# Polarfire SoC register map
Vendor: Microchip; File version: 1.0
CPU: Microchip PolarFire SoC 1.0, little endian
Registers are 32-bit, read-write, reset 0x0 unless marked. A register's access mark holds for its fields unless they carry their own. Offsets are from the block's base; [hi:lo] are bit positions; lines under a group give offsets from that group; {n}, {i} and the like mark numbered series; 'fields as' and 'values as' point back to an identical list.

## TRACE — TRACE Controller
Base 0x23000000
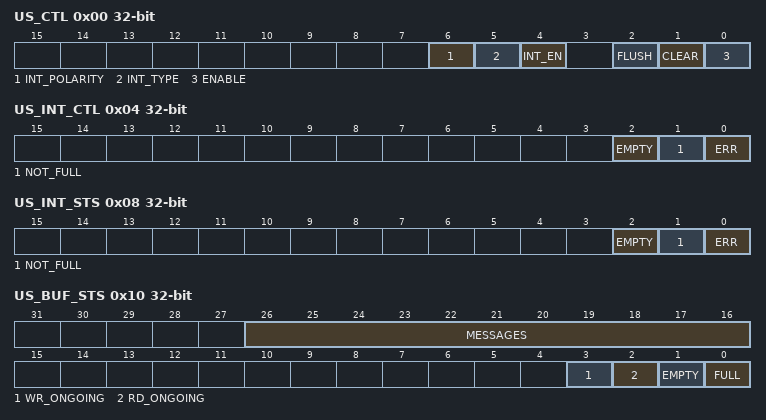
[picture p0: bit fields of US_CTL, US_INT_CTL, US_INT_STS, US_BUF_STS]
0x00 US_CTL — Upstream general control
  [6] INT_POLARITY — Upstream interrupt output is active high when this bit is 1. or active low when 0. Initial value at reset is set according to an instantiation parameter. so it should not be necessary to change the value of this bit.
  [5] INT_TYPE — Upstream interrupt output is a pulse when this bit is 1. or a level when it is 0
  [4] INT_EN — Upstream master interrupt enable
  [2] FLUSH — Flush the message currently being written from upstream message buffer. Must be applied before the last write of a message. Selfclearing. so always reads as zero
  [1] CLEAR — Clear upstream message buffer. Debug option; do not set without consulting UltraSoC
  [0] ENABLE — Upstream enable.
0x04 US_INT_CTL — control of upstream interrupt behaviour
  [2] EMPTY — Enable buffer empty interrupt
  [1] NOT_FULL — Enable buffer not full interrupt
  [0] ERR — Enable upstream error interrupt
0x08 US_INT_STS — upstream interrupt status
  [2] EMPTY — Enable buffer empty interrupt. The upstream message buffer is empty. and there is therefore sufficient space to write an entire message via us_data.
  [1] NOT_FULL — Enable buffer not full interrupt. The upstream message buffer is no longer full. and further message data can be written via us_data
  [0] ERR — Enable upstream error interrupt. This indicates us_data was written when there was no space available in the upstream message buffer (us_buf_sts full bit set).
0x0C US_DATA ro — Upstream message data
  [31:0] DATA rw
0x10 US_BUF_STS ro — upstream buffer status
  [26:16] MESSAGES — Number of whole messages contained in the upstream buffer.
  [3] WR_ONGOING — Write ongoing. Part of a message has been written in to the buffer via us_data.
  [2] RD_ONGOING — Read ongoing. Part of a message has been output from the message interface
  [1] EMPTY — Upstream buffer is empty
  [0] FULL — Upstream buffer is full
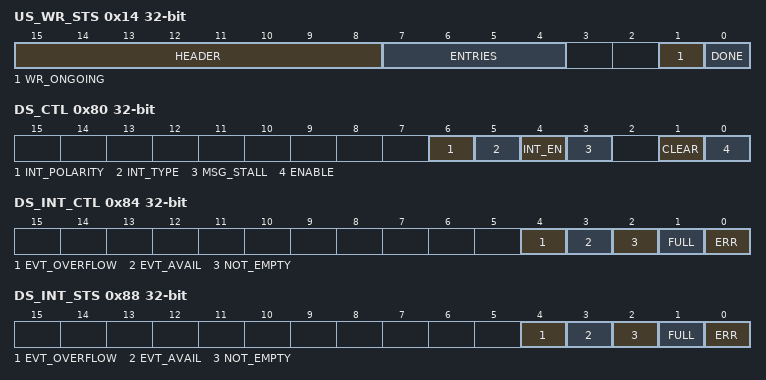
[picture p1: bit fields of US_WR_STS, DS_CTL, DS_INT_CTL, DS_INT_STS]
0x14 US_WR_STS ro — Upstream write status
  [15:8] HEADER — Header (byte 0) of the message being written into upstream message buffer (only valid if wr_ongoing is 1).
  [7:4] ENTRIES — Number of 32-bit words of an incomplete message written into the upstream buffer (only valid if wr_ongoing is 1).
  [1] WR_ONGOING — Write ongoing. Part of a message has been written in to the buffer via us_data
  [0] DONE — Upstream buffer contains a complete message
0x18 US_GP — Upstream general purpose
  [7:0] GP — General purpose location
0x1C US_EVT — Upstream event
  [7:0] EVENT — Event number to send
0x80 DS_CTL — Downstream general control
  [6] INT_POLARITY — Downstream interrupt output is active high when this bit is 1. or active low when 0. Initial value at reset is set according to an instantiation parameter. so it should not be necessary to change the value of this bit
  [5] INT_TYPE — Downstream interrupt output is a pulse when this bit is 1. or a level when it is 0.
  [4] INT_EN — Downstream master interrupt enable.
  [3] MSG_STALL — Stall the downstream message interface to prevent new downstream data accumulating in the downstream buffer. Debug option; do not set without consulting UltraSoC.
  [1] CLEAR — Clear downstream message buffer. Debug option; do not set without consulting UltraSoC
  [0] ENABLE — Downstream enable
0x84 DS_INT_CTL — control of downstream interrupt behaviour
  [4] EVT_OVERFLOW — Enable event FIFO overflow interrupt
  [3] EVT_AVAIL — Enable event available interrupt
  [2] NOT_EMPTY — Enable buffer not empty interrupt
  [1] FULL — Enable buffer full interrupt.
  [0] ERR — Enable downstream error interrupt
0x88 DS_INT_STS — downstream interrupt status
  [4] EVT_OVERFLOW — Event FIFO overflow interrupt. A downstream event was lost because there was no room to store it in the downstream event FIFO
  [3] EVT_AVAIL — Event available interrupt. The downstream event FIFO is no longer empty
  [2] NOT_EMPTY — Downstream buffer not empty interrupt. A new message is available and can be read from ds_data.
  [1] FULL — Downstream buffer full interrupt. The downstream message buffer is full. indicating that no further messages can be accepted and backpressure is being applied to the downstream message interface
  [0] ERR — Downstream error interrupt. This indicates ds_data was read when there was no message data available
0x8C DS_DATA ro — Downstream message data
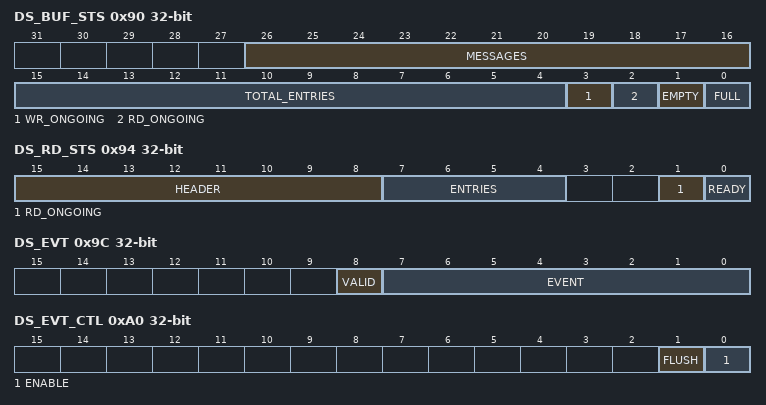
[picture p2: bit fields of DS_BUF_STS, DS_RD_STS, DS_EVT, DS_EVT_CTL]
0x90 DS_BUF_STS ro — Downstream buffer status
  [26:16] MESSAGES — Number of whole messages contained in the downstream buffer
  [15:4] TOTAL_ENTRIES — Number of buffer entries containing valid message data
  [3] WR_ONGOING — Write ongoing. Part of a message has been received from the message interface.
  [2] RD_ONGOING — Read ongoing. Part of a message has been read out of the buffer via ds_data
  [1] EMPTY — Downstream buffer is empty
  [0] FULL — Downstream buffer is full
0x94 DS_RD_STS ro — downstream read status
  [15:8] HEADER — Header (byte 0) of the message being read from the downstream message buffer (only valid if rd_ongoing is 1).
  [7:4] ENTRIES — Number of 32-bit words of a message yet to be read out of the downstream buffer (only valid if rd_ongoing is 1).
  [1] RD_ONGOING — Read ongoing. Part of a message has been read out of the buffer via ds_data
  [0] READY — Downstream buffer contains a complete message ready for reading.
0x9C DS_EVT — Downstream event
  [8] VALID — Event valid
  [7:0] EVENT — Event number received (when valid is 1).
0xA0 DS_EVT_CTL — control of downstream real-time events
  [1] FLUSH — Flush the downstream event FIFO. Once set. all events will be discarded until a zero is written to this bit
  [0] ENABLE — Event FIFO enable. Must be set in order to receive events via ds_evt
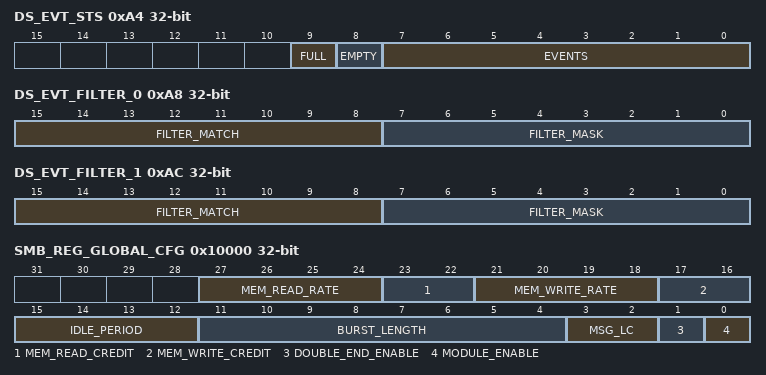
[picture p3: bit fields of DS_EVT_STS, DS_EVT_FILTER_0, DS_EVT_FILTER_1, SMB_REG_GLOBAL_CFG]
0xA4 DS_EVT_STS ro — status of downstream real-time events
  [9] FULL — Indicates that the downstream event FIFO is full
  [8] EMPTY — Indicates that the downstream event FIFO is empty
  [7:0] EVENTS — Number of events in the downstream event FIFO
0xA8 DS_EVT_FILTER_0 — Downstream event filter 0
  [15:8] FILTER_MATCH — Filter match. Capture all real-time events that meet the condition: event & filter_mask == filter_match & filter_mask
  [7:0] FILTER_MASK
0xAC DS_EVT_FILTER_1 — Downstream event filter 1
  fields as DS_EVT_FILTER_0
0x10000 SMB_REG_GLOBAL_CFG — Global configuration
  [27:24] MEM_READ_RATE — Controls the rate at which the read access credit counter is replenished in powers of 2.
  [23:22] MEM_READ_CREDIT — Controls the access credit available to the bus master for read accesses to the system memory.
  [21:18] MEM_WRITE_RATE — Controls the rate at which the write access credit counter is replenished in powers of 2. 0x0 replenishes continuously
  [17:16] MEM_WRITE_CREDIT — Controls the access credit available to the bus master for write accesses to the system memory.
  [15:12] IDLE_PERIOD — Controls the idle message injection timer period
  [11:4] BURST_LENGTH — Programmable burst length for system memory transfers. Defaults to the parameter sys_mem_blen_p
  [3:2] MSG_LC — The logical channel the network message adapter must output messages on.
  [1] DOUBLE_END_ENABLE — Read enable for double-ended buffering mode.
  [0] MODULE_ENABLE — Global enable for the System Memory Buffer. 0-Disable 1-Enable
0x10004 SMB_REG_GLOBAL_EN — Global enable
  [0] MODULE_ENABLE — Global enable for the System Memory Buffer. 0-Disable 1-Enable
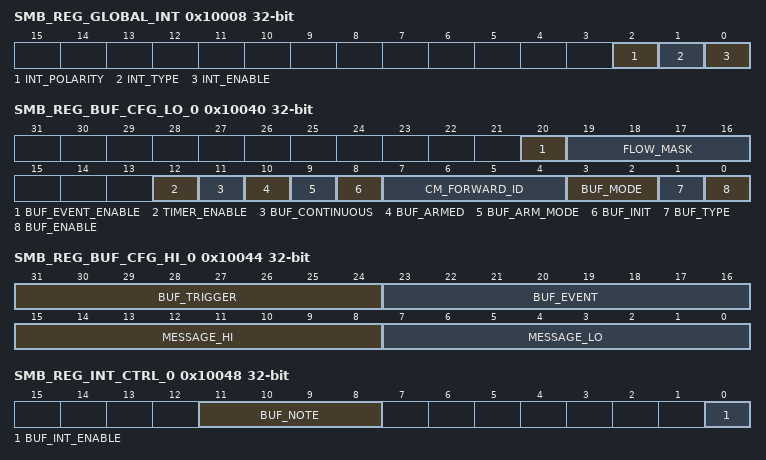
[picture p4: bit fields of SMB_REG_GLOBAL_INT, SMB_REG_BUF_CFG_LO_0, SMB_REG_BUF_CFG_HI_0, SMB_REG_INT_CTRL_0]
0x10008 SMB_REG_GLOBAL_INT — Global interrupt control
  [2] INT_POLARITY — Interrupt polarity: 1 - Active high. 0 - Active low.
  [1] INT_TYPE — Interrupt type: 1 - Pulse, 0 Level.
  [0] INT_ENABLE — Global interrupt enable control
0x1000C SMB_REG_GLOBAL_ID — Global master bus interface ID control
  [31:0] MST_ID
0x10040 SMB_REG_BUF_CFG_LO_0 — Logical buffer configuration (lower 32b) i logical buffer index; i = 0 for 1st buffer
  [20] BUF_EVENT_ENABLE — Enable event generation for the logical buffer when set
  [19:16] FLOW_MASK — Mask to filter the messages accepted based on their flow
  [12] TIMER_ENABLE — Controls whether the purge timer is enabled for a logical buffer. 0-Purge timer disabled 1-Purge timer enabled
  [11] BUF_CONTINUOUS — Set to make the buffer lossless by configuring it to block its message input when in a paused state.
  [10] BUF_ARMED — Set to arm the logical buffer in single shot mode
  [9] BUF_ARM_MODE — Set to enable single-shot mode. clear for automatic rearming
  [8] BUF_INIT — Initialises the buffer when set to 1, application of 0 has no effect. Read as zero
  [7:4] CM_FORWARD_ID — The communicator ID to forward the message stream to upon reading of the logical buffer
  [3:2] BUF_MODE — Buffering modes. 00 : Streaming mode (FIFO) 01 : Trace to mode 10 : Trace from mode 11 : Trace about mode
  [1] BUF_TYPE — Buffer control type: 0 : Double-ended buffering mode (default) 1 : Single-ended buffering mode
  [0] BUF_ENABLE — Logical buffer enable control: 0 : Disable the logical buffer 1 : Enable the logical buffer
0x10044 SMB_REG_BUF_CFG_HI_0 — Logical buffer configuration (upper 32b) i logical buffer index; i = 0 for 1st buffer
  [31:24] BUF_TRIGGER — The real-time event to accept as a trigger when the buffer is configured in a triggered mode
  [23:16] BUF_EVENT — The event to output when a buffer trigger occurs
  [15:8] MESSAGE_HI — Message filter range upper value
  [7:0] MESSAGE_LO — Message filter range lower value.
0x10048 SMB_REG_INT_CTRL_0 — Interrupt control
  [11:8] BUF_NOTE — Selects the buffer status changes that a debugger is to be notified about using a real-time event or interrupt.
  [0] BUF_INT_ENABLE — Logical buffer interrupts enable.
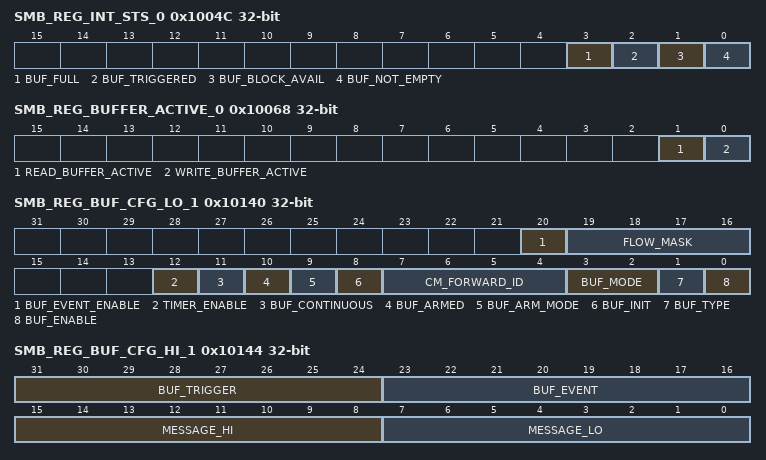
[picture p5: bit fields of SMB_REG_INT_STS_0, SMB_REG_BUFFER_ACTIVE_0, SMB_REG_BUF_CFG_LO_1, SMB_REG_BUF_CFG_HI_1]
0x1004C SMB_REG_INT_STS_0 — Interrupt status
  [3] BUF_FULL — Logical buffer full interrupt
  [2] BUF_TRIGGERED — Logical buffer triggered interrupt
  [1] BUF_BLOCK_AVAIL — Logical buffer memory block available to read interrupt.
  [0] BUF_NOT_EMPTY — Logical buffer changed to not empty interrupt.
0x10050 SMB_REG_BASE_LO_0 — Logical buffer base address (lower 32b)
  [31:0] BASE_ADDR_LO — Memory base address lower 32b for the message buffers
0x10054 SMB_REG_BASE_HI_0 — Logical buffer base address (upper 32b)
  [31:0] BASE_ADDR_HI — Memory base address upper 32b for the message buffers
0x10058 SMB_REG_LIMIT_0 — Logical buffer limit address
  [31:0] LIMIT_ADDR — Memory limit address configuring the end of a logical buffer
0x1005C SMB_REG_RD_ADDR_0 — Memory read address
  [31:0] READ_PTR — Memory read address pointer. Read only if the buffer is enabled in double ended mode
0x10060 SMB_REG_WR_ADDR_0 ro — Memory write address
  [31:0] WRITE_PTR — Memory write address pointer
0x10064 SMB_REG_PURGE_0 — Logical buffer purge
  [0] PURGE — Applying a 1 causes the packer and input FIFO of the logical buffer to be purged.
0x10068 SMB_REG_BUFFER_ACTIVE_0 ro — Logical buffer buffer active
  [1] READ_BUFFER_ACTIVE — Read operations from the buffer are active when 1
  [0] WRITE_BUFFER_ACTIVE — Write operations from the buffer are active when 1
0x10140 SMB_REG_BUF_CFG_LO_1 — Logical buffer configuration (lower 32b) i logical buffer index; i = 0 for 1st buffer
  fields as SMB_REG_BUF_CFG_LO_0
0x10144 SMB_REG_BUF_CFG_HI_1 — Logical buffer configuration (upper 32b) i logical buffer index; i = 0 for 1st buffer
  fields as SMB_REG_BUF_CFG_HI_0
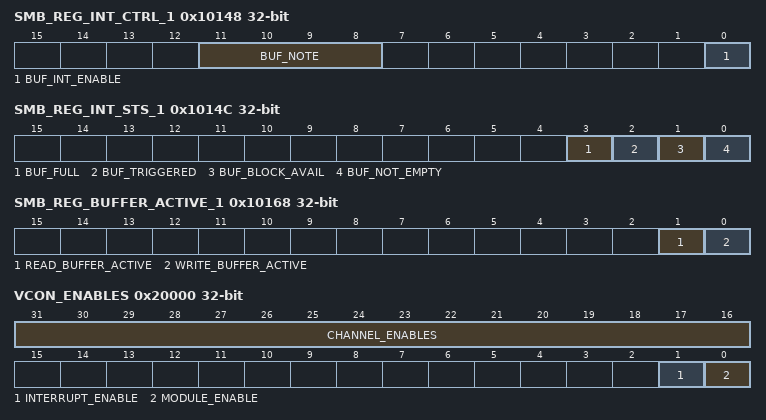
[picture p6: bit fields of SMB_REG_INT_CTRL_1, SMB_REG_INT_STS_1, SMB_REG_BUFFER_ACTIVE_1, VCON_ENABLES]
0x10148 SMB_REG_INT_CTRL_1 — Interrupt control
  fields as SMB_REG_INT_CTRL_0
0x1014C SMB_REG_INT_STS_1 — Interrupt status
  fields as SMB_REG_INT_STS_0
0x10150 SMB_REG_BASE_LO_1 — Logical buffer base address (lower 32b)
  fields as SMB_REG_BASE_LO_0
0x10154 SMB_REG_BASE_HI_1 — Logical buffer base address (upper 32b)
  fields as SMB_REG_BASE_HI_0
0x10158 SMB_REG_LIMIT_1 — Logical buffer limit address
  fields as SMB_REG_LIMIT_0
0x1015C SMB_REG_RD_ADDR_1 — Memory read address
  fields as SMB_REG_RD_ADDR_0
0x10160 SMB_REG_WR_ADDR_1 ro — Memory write address
  [31:0] WRITE_PTR — Memory write address pointer
0x10164 SMB_REG_PURGE_1 — Logical buffer purge
  fields as SMB_REG_PURGE_0
0x10168 SMB_REG_BUFFER_ACTIVE_1 ro — Logical buffer buffer active
  fields as SMB_REG_BUFFER_ACTIVE_0
0x20000 VCON_ENABLES — Virtual Console global enables register
  [31:16] CHANNEL_ENABLES — Channel enable. The enable for channel i corresponds to bit 16 + i.
  [1] INTERRUPT_ENABLE — Global interrupt enable
  [0] MODULE_ENABLE — Global module enable
0x20004 VCON_ENABLES_OR — Logical OR between the value written and the Virtual Console global enables register.
0x20008 VCON_ENABLES_AND — Logical AND between the value written and the Virtual Console group enables register
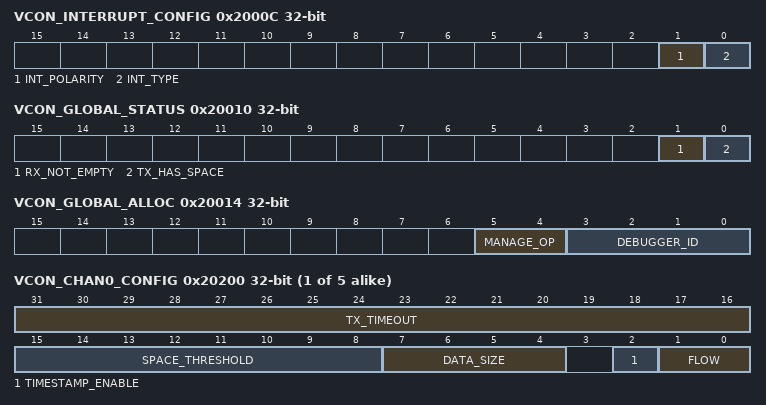
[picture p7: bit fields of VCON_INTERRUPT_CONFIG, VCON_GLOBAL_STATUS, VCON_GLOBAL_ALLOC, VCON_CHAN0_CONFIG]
0x2000C VCON_INTERRUPT_CONFIG — Virtual Console interrupt configuration register
  [1] INT_POLARITY — Interrupt polarity: 0: Active low. 1: Active high. Reset value defined at design time. It should not normally be necessary to change the value of this bit.
  [0] INT_TYPE — Interrupt type: 0: Level. 1: Pulse. Reset to 0.
0x20010 VCON_GLOBAL_STATUS ro — Virtual Console global status register
  [1] RX_NOT_EMPTY — Channel i upstream buffer not empty flag
  [0] TX_HAS_SPACE — Channel i downstream buffer has space flag
0x20014 VCON_GLOBAL_ALLOC — Virtual Console global allocation register
  [5:4] MANAGE_OP — Allocation operation: 00 (get): Requests allocation status of global resource 01 (allocate): Allocate global resource to debugger_id if currently unallocated. 10 (release): Deallocate global resource. 11 (force): Allocate global resource to debugger_id even if this resource is already allocated.
  [3:0] DEBUGGER_ID — ID of debugger or other software API. Zero means unallocated.
0x2007C VCON_CHAN0_BURSTDATA — Virtual Console channel 0 burst data register
  [31:0] BURSTDATA — Write transactions transfer data to the channel i upstream buffer. Read transactions retrieve data from the channel I downstream buffer.
{0x2001C+0xE0*i} VCON_CHAN{i}_BURSTDATA (i=1..4) — Virtual Console channel {i} burst data register
  fields as VCON_CHAN0_BURSTDATA
{0x20200+0x20*i} VCON_CHAN{i}_CONFIG (i=0..4) — Virtual Console channel {i} configuration register
  [31:16] TX_TIMEOUT — Transmit timeout in cycles
  [15:8] SPACE_THRESHOLD — Available space threshold for signalling an interrupt. An interrupt is issued when the available space is greater than this value
  [7:4] DATA_SIZE — The maximum length - in bytes - of the data field in vconsole_data messages. plus one.
  [2] TIMESTAMP_ENABLE — Enable timestamps on vconsole_data messages
  [1:0] FLOW — The flow assigned to flow_control_report and vconsole_data messages
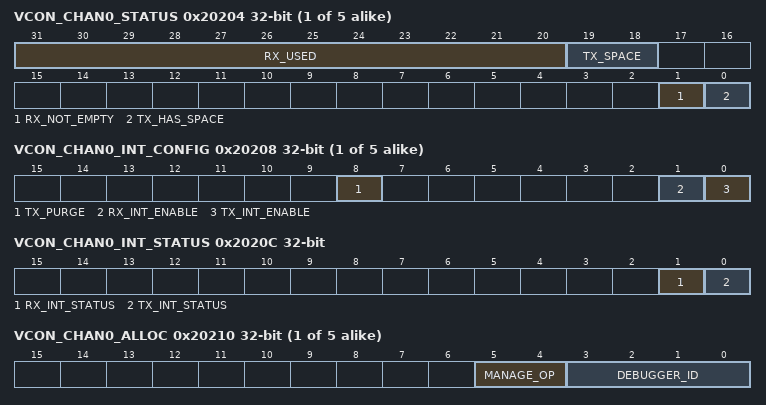
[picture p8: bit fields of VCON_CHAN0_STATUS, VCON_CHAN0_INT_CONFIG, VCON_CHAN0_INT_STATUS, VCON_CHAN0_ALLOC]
{0x20204+0x20*i} VCON_CHAN{i}_STATUS ro (i=0..4) — Virtual Console channel {i} status register
  [31:20] RX_USED — Channel i upstream buffer usage in bytes
  [19:18] TX_SPACE — Channel i downstream buffer space in bytes
  [1] RX_NOT_EMPTY — Channel i upstream buffer not empty flag
  [0] TX_HAS_SPACE — Channel i downstream buffer has space flag
{0x20208+0x20*i} VCON_CHAN{i}_INT_CONFIG (i=0..4) — Virtual Console channel {i} interrupt configuration register
  [8] TX_PURGE — Purge channel i downstream buffer. Read as 1 until purge request is complete
  [1] RX_INT_ENABLE — Enable interrupt when the channel i upstream buffer state transitions from empty to not empty
  [0] TX_INT_ENABLE — Enable interrupt when the channel i downstream buffer space available is greater than space_threshold.
0x2020C VCON_CHAN0_INT_STATUS ro — Virtual Console channel i interrupt status register
  [1] RX_INT_STATUS — Status of channel i RX interrupt (upstream buffer).
  [0] TX_INT_STATUS — Status of channel i TX interrupt (downstream buffer).
{0x20210+0x20*i} VCON_CHAN{i}_ALLOC (i=0..4) — Virtual Console channel {i} allocation register.
  [5:4] MANAGE_OP — Allocation operation: 00 (get): Requests allocation status of global resource 01 (allocate): Allocate global resource to debugger_id if currently unallocated. 10 (release): Deallocate global resource. 11 (force): Allocate global resource to debugger_id even if this resource is already allocated.
  [3:0] DEBUGGER_ID — ID of debugger or other software API. Zero means unallocated
{0x20214+0x20*i} VCON_CHAN{i}_DATA (i=0..4) — Virtual Console channel {i} data register
  [31:0] DATA — Write transactions transfer a single byte to the channel i upstream buffer. Read transactions retrieve a single byte from the channel i downstream buffer.
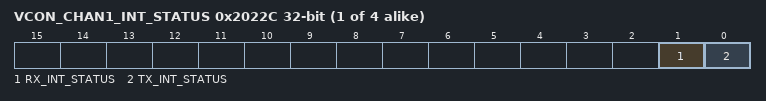
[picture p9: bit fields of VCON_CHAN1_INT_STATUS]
{0x2020C+0x20*i} VCON_CHAN{i}_INT_STATUS ro (i=1..4) — Virtual Console channel {i} interrupt status register
  fields as VCON_CHAN0_INT_STATUS
